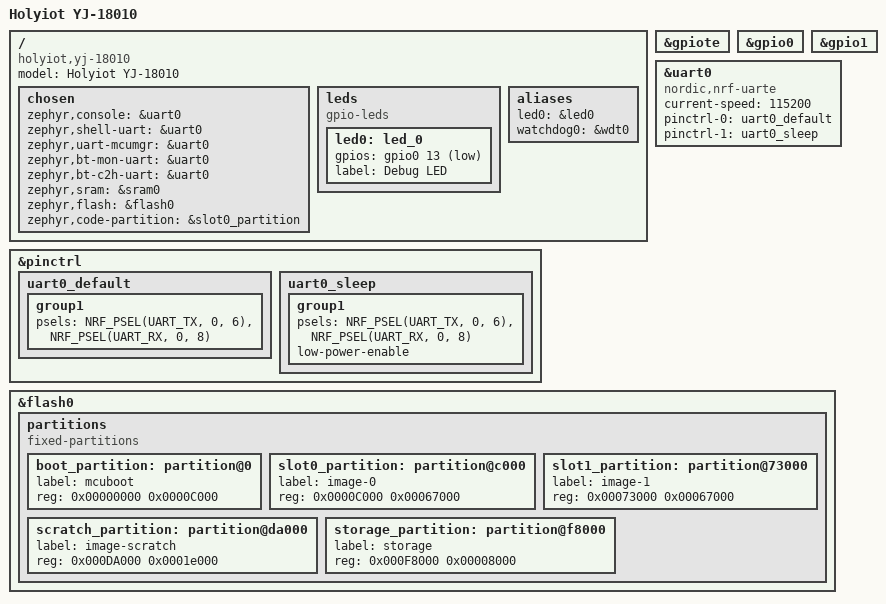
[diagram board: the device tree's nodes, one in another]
/*
 * Holyiot YJ-18010 - nRF52840 Module with Ceramic Antenna
 * Board definition for Zephyr RTOS
 */

/dts-v1/;
#include <nordic/nrf52840_qiaa.dtsi>

/ {
	model = "Holyiot YJ-18010";
	compatible = "holyiot,yj-18010";

	chosen {
		zephyr,console = &uart0;
		zephyr,shell-uart = &uart0;
		zephyr,uart-mcumgr = &uart0;
		zephyr,bt-mon-uart = &uart0;
		zephyr,bt-c2h-uart = &uart0;
		zephyr,sram = &sram0;
		zephyr,flash = &flash0;
		zephyr,code-partition = &slot0_partition;
	};

	/* Optional: LED for debugging (connect external if needed) */
	leds {
		compatible = "gpio-leds";
		led0: led_0 {
			gpios = <&gpio0 13 GPIO_ACTIVE_LOW>;
			label = "Debug LED";
		};
	};

	/* Aliases */
	aliases {
		led0 = &led0;
		watchdog0 = &wdt0;
	};
};

&gpiote {
	status = "okay";
};

&gpio0 {
	status = "okay";
};

&gpio1 {
	status = "okay";
};

/* UART for debugging (optional - can be disabled for production) */
&uart0 {
	compatible = "nordic,nrf-uarte";
	status = "okay";
	current-speed = <115200>;
	pinctrl-0 = <&uart0_default>;
	pinctrl-1 = <&uart0_sleep>;
	pinctrl-names = "default", "sleep";
};

&pinctrl {
	uart0_default: uart0_default {
		group1 {
			psels = <NRF_PSEL(UART_TX, 0, 6)>,
			        <NRF_PSEL(UART_RX, 0, 8)>;
		};
	};

	uart0_sleep: uart0_sleep {
		group1 {
			psels = <NRF_PSEL(UART_TX, 0, 6)>,
			        <NRF_PSEL(UART_RX, 0, 8)>;
			low-power-enable;
		};
	};
};

&flash0 {
	partitions {
		compatible = "fixed-partitions";
		#address-cells = <1>;
		#size-cells = <1>;

		/* Bootloader (optional) */
		boot_partition: partition@0 {
			label = "mcuboot";
			reg = <0x00000000 0x0000C000>;
		};

		/* Application */
		slot0_partition: partition@c000 {
			label = "image-0";
			reg = <0x0000C000 0x00067000>;
		};

		/* OTA slot (optional) */
		slot1_partition: partition@73000 {
			label = "image-1";
			reg = <0x00073000 0x00067000>;
		};

		/* Scratch for OTA */
		scratch_partition: partition@da000 {
			label = "image-scratch";
			reg = <0x000DA000 0x0001e000>;
		};

		/* Storage for NVS */
		storage_partition: partition@f8000 {
			label = "storage";
			reg = <0x000F8000 0x00008000>;
		};
	};
};
